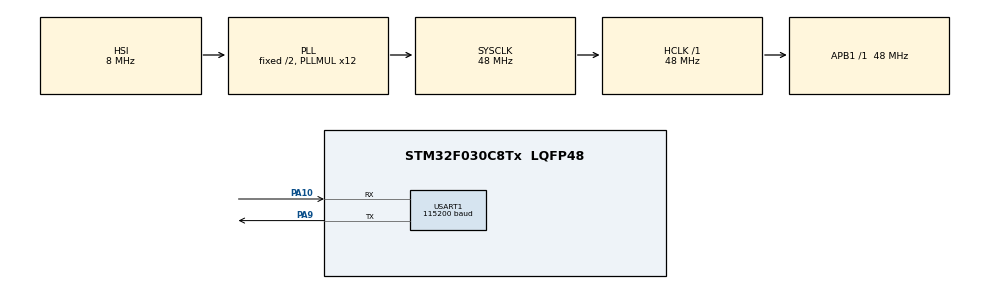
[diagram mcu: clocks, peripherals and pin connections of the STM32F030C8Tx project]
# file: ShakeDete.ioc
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FREERTOS.Tasks01=defaultTask,0,128,StartDefaultTask,Default
Mcu.Family=STM32F0
Mcu.Name=STM32F030C8Tx
Mcu.Package=LQFP48
NVIC.TIM1_BRK_UP_TRG_COM_IRQn=true\:0\:0\:false
NVIC.TimeBase=TIM1_BRK_UP_TRG_COM_IRQn
NVIC.TimeBaseIP=TIM1
NVIC.USART1_IRQn=true\:3\:0\:false
PA10.Mode=Asynchronous
PA10.Signal=USART1_RX
PA9.Mode=Asynchronous
PA9.Signal=USART1_TX
ProjectManager.HeapSize=0x400
ProjectManager.StackSize=0x200
ProjectManager.TargetToolchain=MDK-ARM V5
RCC.AHBFreq_Value=48000000
RCC.APB1Freq_Value=48000000
RCC.APB1TimFreq_Value=48000000
RCC.HCLKFreq_Value=48000000
RCC.PLLMUL=RCC_PLL_MUL12
RCC.SYSCLKFreq_VALUE=48000000
RCC.SYSCLKSource=RCC_SYSCLKSOURCE_PLLCLK
USART1.BaudRate=115200
VP_FREERTOS_VS_ENABLE.Mode=Enabled
VP_SYS_VS_tim1.Mode=TIM1
board=ShakeDete

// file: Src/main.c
/**
  ******************************************************************************
  * File Name          : main.c
  * Description        : Main program body
  ******************************************************************************
  *
  * COPYRIGHT(c) 2016 STMicroelectronics
  *
  * Redistribution and use in source and binary forms, with or without modification,
  * are permitted provided that the following conditions are met:
  *   1. Redistributions of source code must retain the above copyright notice,
  *      this list of conditions and the following disclaimer.
  *   2. Redistributions in binary form must reproduce the above copyright notice,
  *      this list of conditions and the following disclaimer in the documentation
  *      and/or other materials provided with the distribution.
  *   3. Neither the name of STMicroelectronics nor the names of its contributors
  *      may be used to endorse or promote products derived from this software
  *      without specific prior written permission.
  *
  * THIS SOFTWARE IS PROVIDED BY THE COPYRIGHT HOLDERS AND CONTRIBUTORS "AS IS"
  * AND ANY EXPRESS OR IMPLIED WARRANTIES, INCLUDING, BUT NOT LIMITED TO, THE
  * IMPLIED WARRANTIES OF MERCHANTABILITY AND FITNESS FOR A PARTICULAR PURPOSE ARE
  * DISCLAIMED. IN NO EVENT SHALL THE COPYRIGHT HOLDER OR CONTRIBUTORS BE LIABLE
  * FOR ANY DIRECT, INDIRECT, INCIDENTAL, SPECIAL, EXEMPLARY, OR CONSEQUENTIAL
  * DAMAGES (INCLUDING, BUT NOT LIMITED TO, PROCUREMENT OF SUBSTITUTE GOODS OR
  * SERVICES; LOSS OF USE, DATA, OR PROFITS; OR BUSINESS INTERRUPTION) HOWEVER
  * CAUSED AND ON ANY THEORY OF LIABILITY, WHETHER IN CONTRACT, STRICT LIABILITY,
  * OR TORT (INCLUDING NEGLIGENCE OR OTHERWISE) ARISING IN ANY WAY OUT OF THE USE
  * OF THIS SOFTWARE, EVEN IF ADVISED OF THE POSSIBILITY OF SUCH DAMAGE.
  *
  ******************************************************************************
  */
#include "stm32f0xx_hal.h"
#include "cmsis_os.h"

/* USER CODE BEGIN Includes */
#include "../App/app.h"
/* USER CODE END Includes */

UART_HandleTypeDef huart1;

osThreadId defaultTaskHandle;

/* USER CODE BEGIN PV */
/* Private variables ---------------------------------------------------------*/

/* USER CODE END PV */

void SystemClock_Config(void);
static void MX_GPIO_Init(void);
static void MX_USART1_UART_Init(void);
void StartDefaultTask(void const * argument);

/* USER CODE BEGIN PFP */
/* Private function prototypes -----------------------------------------------*/

/* USER CODE END PFP */

int main(void)
{

  /* MCU Configuration----------------------------------------------------------*/

  /* Reset of all peripherals, Initializes the Flash interface and the Systick. */
  HAL_Init();

  /* Configure the system clock */
  SystemClock_Config();

  /* Initialize all configured peripherals */
  MX_GPIO_Init();
  MX_USART1_UART_Init();

  /* Create the thread(s) */
  /* definition and creation of defaultTask */
  osThreadDef(defaultTask, StartDefaultTask, osPriorityNormal, 0, 128);
  defaultTaskHandle = osThreadCreate(osThread(defaultTask), NULL);

  /* USER CODE BEGIN RTOS_THREADS */
  /* add threads, ... */
  appStart();
  /* USER CODE END RTOS_THREADS */

  /* Start scheduler */
  osKernelStart();

  /* We should never get here as control is now taken by the scheduler */

  /* Infinite loop */
  while (1)
  {

  }

}

/** System Clock Configuration
*/
void SystemClock_Config(void)
{

  RCC_OscInitTypeDef RCC_OscInitStruct;
  RCC_ClkInitTypeDef RCC_ClkInitStruct;
  RCC_PeriphCLKInitTypeDef PeriphClkInit;

  RCC_OscInitStruct.OscillatorType = RCC_OSCILLATORTYPE_HSI;
  RCC_OscInitStruct.HSIState = RCC_HSI_ON;
  RCC_OscInitStruct.HSICalibrationValue = 16;
  RCC_OscInitStruct.PLL.PLLState = RCC_PLL_ON;
  RCC_OscInitStruct.PLL.PLLSource = RCC_PLLSOURCE_HSI;
  RCC_OscInitStruct.PLL.PLLMUL = RCC_PLL_MUL12;
  RCC_OscInitStruct.PLL.PREDIV = RCC_PREDIV_DIV1;
  HAL_RCC_OscConfig(&RCC_OscInitStruct);

  RCC_ClkInitStruct.ClockType = RCC_CLOCKTYPE_HCLK|RCC_CLOCKTYPE_SYSCLK
                              |RCC_CLOCKTYPE_PCLK1;
  RCC_ClkInitStruct.SYSCLKSource = RCC_SYSCLKSOURCE_PLLCLK;
  RCC_ClkInitStruct.AHBCLKDivider = RCC_SYSCLK_DIV1;
  RCC_ClkInitStruct.APB1CLKDivider = RCC_HCLK_DIV1;
  HAL_RCC_ClockConfig(&RCC_ClkInitStruct, FLASH_LATENCY_1);

  PeriphClkInit.PeriphClockSelection = RCC_PERIPHCLK_USART1;
  PeriphClkInit.Usart1ClockSelection = RCC_USART1CLKSOURCE_PCLK1;
  HAL_RCCEx_PeriphCLKConfig(&PeriphClkInit);

  HAL_SYSTICK_Config(HAL_RCC_GetHCLKFreq()/1000);

  HAL_SYSTICK_CLKSourceConfig(SYSTICK_CLKSOURCE_HCLK);

  /* SysTick_IRQn interrupt configuration */
  HAL_NVIC_SetPriority(SysTick_IRQn, 3, 0);
}

/* USART1 init function */
void MX_USART1_UART_Init(void)
{

  huart1.Instance = USART1;
  huart1.Init.BaudRate = 115200;
  huart1.Init.WordLength = UART_WORDLENGTH_8B;
  huart1.Init.StopBits = UART_STOPBITS_1;
  huart1.Init.Parity = UART_PARITY_NONE;
  huart1.Init.Mode = UART_MODE_TX_RX;
  huart1.Init.HwFlowCtl = UART_HWCONTROL_NONE;
  huart1.Init.OverSampling = UART_OVERSAMPLING_16;
  huart1.Init.OneBitSampling = UART_ONEBIT_SAMPLING_DISABLED ;
  huart1.AdvancedInit.AdvFeatureInit = UART_ADVFEATURE_NO_INIT;
  HAL_UART_Init(&huart1);

}

/** Pinout Configuration
*/
void MX_GPIO_Init(void)
{

  /* GPIO Ports Clock Enable */
  __GPIOA_CLK_ENABLE();

}

/* StartDefaultTask function */
void StartDefaultTask(void const * argument)
{

  for(;;)
  {
    osDelay(1);
  }
}

/************************ (C) COPYRIGHT STMicroelectronics *****END OF FILE****/
